# STM32F7x6 register map
File version: 1.6
CPU: CM7 r0p1, little endian, MPU, FPU, 4 interrupt priority bits
Registers are 32-bit, read-write, reset 0x0 unless marked. A register's access mark holds for its fields unless they carry their own. Offsets are from the block's base; [hi:lo] are bit positions; {n}, {i} and the like mark numbered series; 'fields as' and 'values as' point back to an identical list.

## RTC — Real-time clock
Base 0x40002800
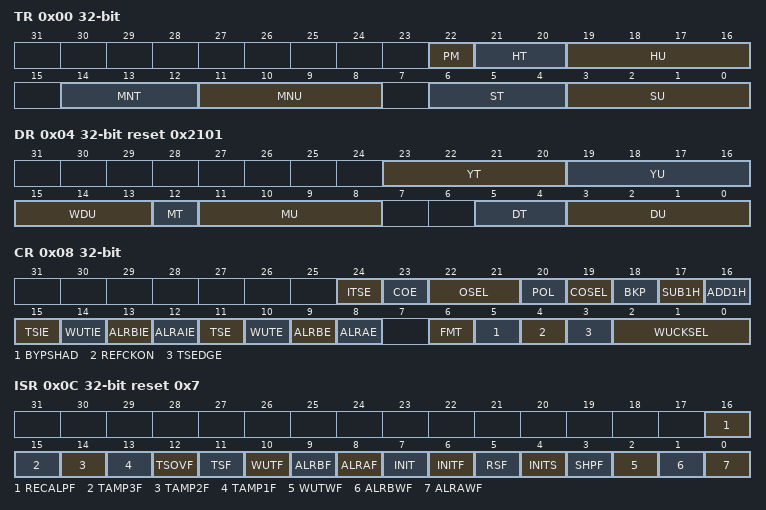
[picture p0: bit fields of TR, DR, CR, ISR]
0x00 TR — time register
  [22] PM — AM/PM notation
    0=AM (AM or 24-hour format); 1=PM
  [21:20] HT — Hour tens in BCD format
  [19:16] HU — Hour units in BCD format
  [14:12] MNT — Minute tens in BCD format
  [11:8] MNU — Minute units in BCD format
  [6:4] ST — Second tens in BCD format
  [3:0] SU — Second units in BCD format
0x04 DR reset 0x2101 — date register
  [23:20] YT — Year tens in BCD format
  [19:16] YU — Year units in BCD format
  [15:13] WDU range 1..7 — Week day units
  [12] MT — Month tens in BCD format
    0=Zero (Month tens is 0); 1=One (Month tens is 1)
  [11:8] MU — Month units in BCD format
  [5:4] DT — Date tens in BCD format
  [3:0] DU — Date units in BCD format
0x08 CR — control register
  [24] ITSE — timestamp on internal event enable
  [23] COE — Calibration output enable
    0=Disabled (Calibration output disabled); 1=Enabled (Calibration output enabled)
  [22:21] OSEL — Output selection
    0=Disabled (Output disabled); 1=Alarm A output enabled; 2=Alarm B output enabled; 3=Wakeup output enabled
  [20] POL — Output polarity
    0=High (The pin is high when ALRAF/ALRBF/WUTF is asserted (depending on OSEL[1:0])); 1=Low (The pin is low when ALRAF/ALRBF/WUTF is asserted (depending on OSEL[1:0]))
  [19] COSEL — Calibration output selection
    0=CalFreq_512Hz (Calibration output is 512 Hz (with default prescaler setting)); 1=CalFreq_1Hz (Calibration output is 1 Hz (with default prescaler setting))
  [18] BKP — Backup
    0=DST_Not_Changed (Daylight Saving Time change has not been performed); 1=DST_Changed (Daylight Saving Time change has been performed)
  [17] SUB1H — Subtract 1 hour (winter time change)
    on write: 1=Sub1 (Subtracts 1 hour to the current time. This can be used for winter time change outside initialization mode)
  [16] ADD1H — Add 1 hour (summer time change)
    on write: 1=Add1 (Adds 1 hour to the current time. This can be used for summer time change outside initialization mode)
  [15] TSIE — Time-stamp interrupt enable
    0=Disabled (Time-stamp Interrupt disabled); 1=Enabled (Time-stamp Interrupt enabled)
  [14] WUTIE — Wakeup timer interrupt enable
    0=Disabled (Wakeup timer interrupt disabled); 1=Enabled (Wakeup timer interrupt enabled)
  [13] ALRBIE — Alarm B interrupt enable
    0=Disabled (Alarm B Interrupt disabled); 1=Enabled (Alarm B Interrupt enabled)
  [12] ALRAIE — Alarm A interrupt enable
    0=Disabled (Alarm A interrupt disabled); 1=Enabled (Alarm A interrupt enabled)
  [11] TSE — Time stamp enable
    0=Disabled (Timestamp disabled); 1=Enabled (Timestamp enabled)
  [10] WUTE — Wakeup timer enable
    0=Disabled (Wakeup timer disabled); 1=Enabled (Wakeup timer enabled)
  [9] ALRBE — Alarm B enable
    0=Disabled (Alarm B disabled); 1=Enabled (Alarm B enabled)
  [8] ALRAE — Alarm A enable
    0=Disabled (Alarm A disabled); 1=Enabled (Alarm A enabled)
  [6] FMT — Hour format
    0=Twenty_Four_Hour (24 hour/day format); 1=AM_PM (AM/PM hour format)
  [5] BYPSHAD — Bypass the shadow registers
    0=ShadowReg (Calendar values (when reading from RTC_SSR, RTC_TR, and RTC_DR) are taken from the shadow registers, which are updated once every two RTCCLK cycles); 1=BypassShadowReg (Calendar values (when reading from RTC_SSR, RTC_TR, and RTC_DR) are taken directly from the calendar counters)
  [4] REFCKON — Reference clock detection enable (50 or 60 Hz)
    0=Disabled (RTC_REFIN detection disabled); 1=Enabled (RTC_REFIN detection enabled)
  [3] TSEDGE — Time-stamp event active edge
    0=RisingEdge (RTC_TS input rising edge generates a time-stamp event); 1=FallingEdge (RTC_TS input falling edge generates a time-stamp event)
  [2:0] WUCKSEL — Wakeup clock selection
    0=Div16 (RTC/16 clock is selected); 1=Div8 (RTC/8 clock is selected); 2=Div4 (RTC/4 clock is selected); 3=Div2 (RTC/2 clock is selected); 4=ClockSpare (ck_spre (usually 1 Hz) clock is selected); 6=ClockSpareWithOffset (ck_spre (usually 1 Hz) clock is selected and 2^16 is added to the WUT counter value)
0x0C ISR access per field reset 0x7 — initialization and status register
  [16] RECALPF ro — Recalibration pending Flag
    on read: 1=Pending (The RECALPF status flag is automatically set to 1 when software writes to the RTC_CALR register, indicating that the RTC_CALR register is blocked. When the new calibration settings are taken into account, this bit returns to 0)
  [15] TAMP3F rw write-0-clears — RTC_TAMP3 detection flag
    on read: 1=Tampered (This flag is set by hardware when a tamper detection event is detected on the RTC_TAMPx input) | on write: 0=Clear (Flag cleared by software writing 0)
  [14] TAMP2F rw write-0-clears — RTC_TAMP2 detection flag
    values as TAMP3F
  [13] TAMP1F rw write-0-clears — Tamper detection flag
    values as TAMP3F
  [12] TSOVF rw write-0-clears — Time-stamp overflow flag
    on read: 1=Overflow (This flag is set by hardware when a time-stamp event occurs while TSF is already set) | on write: 0=Clear (This flag is cleared by software by writing 0)
  [11] TSF rw write-0-clears — Time-stamp flag
    on read: 1=TimestampEvent (This flag is set by hardware when a time-stamp event occurs) | on write: 0=Clear (This flag is cleared by software by writing 0)
  [10] WUTF rw write-0-clears — Wakeup timer flag
    on read: 1=Zero (This flag is set by hardware when the wakeup auto-reload counter reaches 0) | on write: 0=Clear (This flag is cleared by software by writing 0)
  [9] ALRBF rw write-0-clears — Alarm B flag
    on read: 1=Match (This flag is set by hardware when the time/date registers (RTC_TR and RTC_DR) match the Alarm B register (RTC_ALRMBR)) | on write: 0=Clear (This flag is cleared by software by writing 0)
  [8] ALRAF rw write-0-clears — Alarm A flag
    on read: 1=Match (This flag is set by hardware when the time/date registers (RTC_TR and RTC_DR) match the Alarm A register (RTC_ALRMAR)) | on write: 0=Clear (This flag is cleared by software by writing 0)
  [7] INIT rw — Initialization mode
    0=FreeRunningMode; 1=InitMode (Initialization mode used to program time and date register (RTC_TR and RTC_DR), and prescaler register (RTC_PRER). Counters are stopped and start counting from the new value when INIT is reset.)
  [6] INITF ro — Initialization flag
    on read: 0=NotAllowed (Calendar registers update is not allowed); 1=Allowed (Calendar registers update is allowed)
  [5] RSF rw write-0-clears — Registers synchronization flag
    on read: 0=NotSynced (Calendar shadow registers not yet synchronized); 1=Synced (Calendar shadow registers synchronized) | on write: 0=Clear (This flag is cleared by software by writing 0)
  [4] INITS ro — Initialization status flag
    on read: 0=NotInitalized (Calendar has not been initialized); 1=Initalized (Calendar has been initialized)
  [3] SHPF rw — Shift operation pending
    on read: 0=NoShiftPending (No shift operation is pending); 1=ShiftPending (A shift operation is pending)
  [2] WUTWF ro — Wakeup timer write flag
    on read: 0=UpdateNotAllowed (Wakeup timer configuration update not allowed); 1=UpdateAllowed (Wakeup timer configuration update allowed)
  [1] ALRBWF ro — Alarm B write flag
    on read: 0=UpdateNotAllowed (Alarm update not allowed); 1=UpdateAllowed (Alarm update allowed)
  [0] ALRAWF ro — Alarm A write flag
    values as ALRBWF
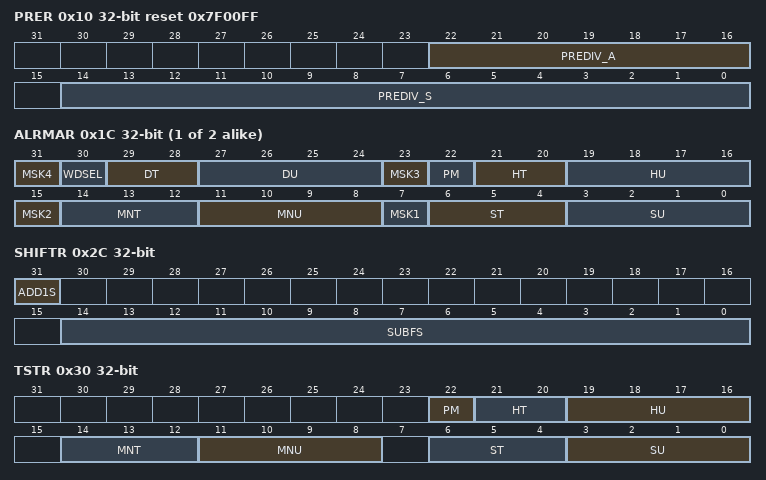
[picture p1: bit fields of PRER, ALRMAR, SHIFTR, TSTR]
0x10 PRER reset 0x7F00FF — prescaler register
  [22:16] PREDIV_A — Asynchronous prescaler factor
  [14:0] PREDIV_S — Synchronous prescaler factor
0x14 WUTR reset 0xFFFF — wakeup timer register
  [15:0] WUT — Wakeup auto-reload value bits
0x1C ALRM{x}R (x=A,B; step 0x4) — Alarm register
  [31] MSK4 — Alarm date mask
    0=Mask (Alarm set if the date/day match); 1=NotMask (Date/day don’t care in Alarm comparison)
  [30] WDSEL — Week day selection
    0=DateUnits (DU[3:0] represents the date units); 1=WeekDay (DU[3:0] represents the week day. DT[1:0] is don’t care.)
  [29:28] DT — Date tens in BCD format
  [27:24] DU — Date units or day in BCD format
  [23] MSK3 — Alarm hours mask
    values as MSK4
  [22] PM — AM/PM notation
    0=AM (AM or 24-hour format); 1=PM
  [21:20] HT — Hour tens in BCD format
  [19:16] HU — Hour units in BCD format
  [15] MSK2 — Alarm minutes mask
    values as MSK4
  [14:12] MNT — Minute tens in BCD format
  [11:8] MNU — Minute units in BCD format
  [7] MSK1 — Alarm seconds mask
    values as MSK4
  [6:4] ST — Second tens in BCD format
  [3:0] SU — Second units in BCD format
0x24 WPR wo — write protection register
  [7:0] KEY — Write protection key
0x28 SSR ro — sub second register
  [15:0] SS — Sub second value
0x2C SHIFTR wo — shift control register
  [31] ADD1S — Add one second
    on write: 1=Add1 (Add one second to the clock/calendar)
  [14:0] SUBFS — Subtract a fraction of a second
0x30 TSTR — time stamp time register
  fields as TR
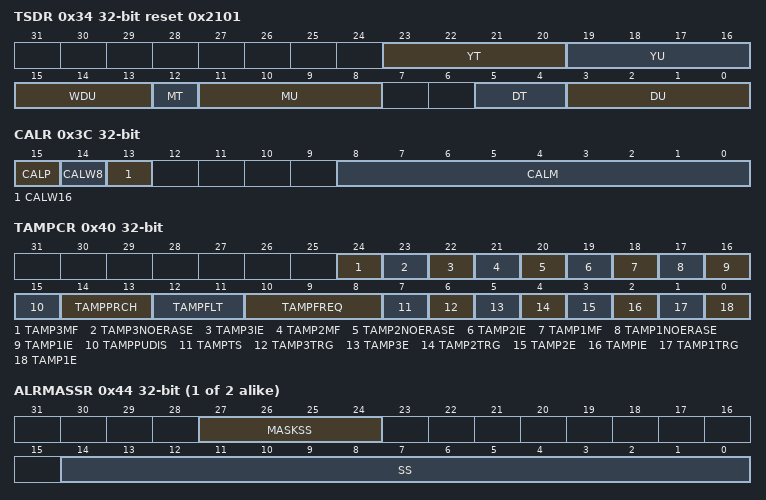
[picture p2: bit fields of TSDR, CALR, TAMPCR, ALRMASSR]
0x34 TSDR reset 0x2101 — time stamp date register
  fields as DR
0x38 TSSSR ro — timestamp sub second register
  [15:0] SS — Sub second value
0x3C CALR — calibration register
  [15] CALP — Increase frequency of RTC by 488.5 ppm
    0=NoChange (No RTCCLK pulses are added); 1=IncreaseFreq (One RTCCLK pulse is effectively inserted every 2^11 pulses (frequency increased by 488.5 ppm))
  [14] CALW8 — Use an 8-second calibration cycle period
    1=Eight_Second (When CALW8 is set to ‘1’, the 8-second calibration cycle period is selected)
  [13] CALW16 — Use a 16-second calibration cycle period
    1=Sixteen_Second (When CALW16 is set to ‘1’, the 16-second calibration cycle period is selected.This bit must not be set to ‘1’ if CALW8=1)
  [8:0] CALM — Calibration minus
0x40 TAMPCR — tamper configuration register
  [24] TAMP3MF — Tamper 3 mask flag
  [23] TAMP3NOERASE — Tamper 3 no erase
  [22] TAMP3IE — Tamper 3 interrupt enable
  [21] TAMP2MF — Tamper 2 mask flag
  [20] TAMP2NOERASE — Tamper 2 no erase
  [19] TAMP2IE — Tamper 2 interrupt enable
  [18] TAMP1MF — Tamper 1 mask flag
  [17] TAMP1NOERASE — Tamper 1 no erase
  [16] TAMP1IE — Tamper 1 interrupt enable
  [15] TAMPPUDIS — TAMPER pull-up disable
  [14:13] TAMPPRCH — Tamper precharge duration
  [12:11] TAMPFLT — Tamper filter count
  [10:8] TAMPFREQ — Tamper sampling frequency
  [7] TAMPTS — Activate timestamp on tamper detection event
  [6] TAMP3TRG — Active level for tamper 3
  [5] TAMP3E — Tamper 3 detection enable
  [4] TAMP2TRG — Active level for tamper 2
  [3] TAMP2E — Tamper 2 detection enable
  [2] TAMPIE — Tamper interrupt enable
  [1] TAMP1TRG — Active level for tamper 1
  [0] TAMP1E — Tamper 1 detection enable
0x44 ALRM{x}SSR (x=A,B; step 0x4) — Alarm sub-second register
  [27:24] MASKSS — Mask the most-significant bits starting at this bit
  [14:0] SS — Sub seconds value
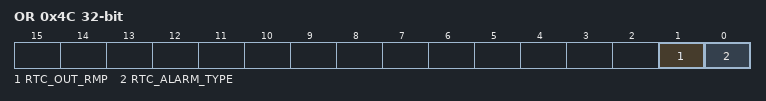
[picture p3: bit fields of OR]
0x4C OR — option register
  [1] RTC_OUT_RMP — RTC_OUT remap
  [0] RTC_ALARM_TYPE — RTC_ALARM on PC13 output type
{0x50+4i} BKP{i}R (i=0..31) — backup register
  [31:0] BKP
